# STM32H733xx register map
File version: 1.0
Registers are 32-bit, access not given, reset 0x0 unless marked. A register's access mark holds for its fields unless they carry their own. Offsets are from the block's base; [hi:lo] are bit positions; {n}, {i} and the like mark numbered series; 'fields as' and 'values as' point back to an identical list.

## FDCAN_CCU
Base 0x4000A800
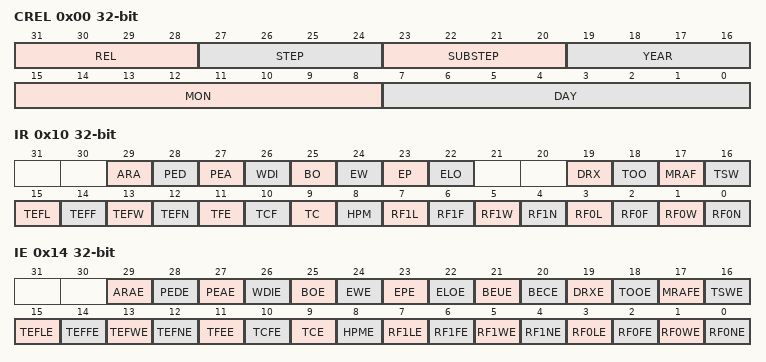
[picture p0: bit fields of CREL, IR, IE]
0x00 CREL
  [31:28] REL, [27:24] STEP, [23:20] SUBSTEP, [19:16] YEAR, [15:8] MON, [7:0] DAY
0x04 CCFG
0x08 CSTAT
0x0C CWD
0x10 IR
  [29] ARA, [28] PED, [27] PEA, [26] WDI, [25] BO, [24] EW, [23] EP, [22] ELO, [19] DRX, [18] TOO, [17] MRAF, [16] TSW, [15] TEFL, [14] TEFF, [13] TEFW, [12] TEFN, [11] TFE, [10] TCF, [9] TC, [8] HPM, [7] RF1L, [6] RF1F, [5] RF1W, [4] RF1N, [3] RF0L, [2] RF0F, [1] RF0W, [0] RF0N
0x14 IE
  [29] ARAE, [28] PEDE, [27] PEAE, [26] WDIE, [25] BOE, [24] EWE, [23] EPE, [22] ELOE, [21] BEUE, [20] BECE, [19] DRXE, [18] TOOE, [17] MRAFE, [16] TSWE, [15] TEFLE, [14] TEFFE, [13] TEFWE, [12] TEFNE, [11] TFEE, [10] TCFE, [9] TCE, [8] HPME, [7] RF1LE, [6] RF1FE, [5] RF1WE, [4] RF1NE, [3] RF0LE, [2] RF0FE, [1] RF0WE, [0] RF0NE

## SAI1
Base 0x40015800
Same registers: SAI4 0x58005400
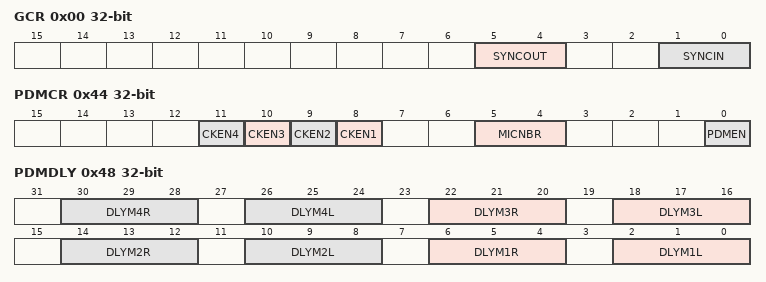
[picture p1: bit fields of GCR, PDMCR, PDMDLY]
0x00 GCR
  [5:4] SYNCOUT, [1:0] SYNCIN
0x04 CR1A
0x08 CR2A
0x10 FRCRA
0x1C SLOTRA
0x24 CR1B
0x28 CR2B
0x2C IMRA
0x30 FRCRB
0x3C SLOTRB
0x40 SRA
0x44 PDMCR
  [n+7] CKEN{n} (n=1..4), [5:4] MICNBR, [0] PDMEN
0x48 PDMDLY
  [8n-2:8n-4] DLYM{n}R (n=1..4), [8n-6:8n-8] DLYM{n}L (n=1..4)
0x4C IMRB
0x58 CLRFRA
0x60 SRB
0x74 DRA
0x78 CLRFRB
0x94 DRB

## DFSDM1
Base 0x40017800
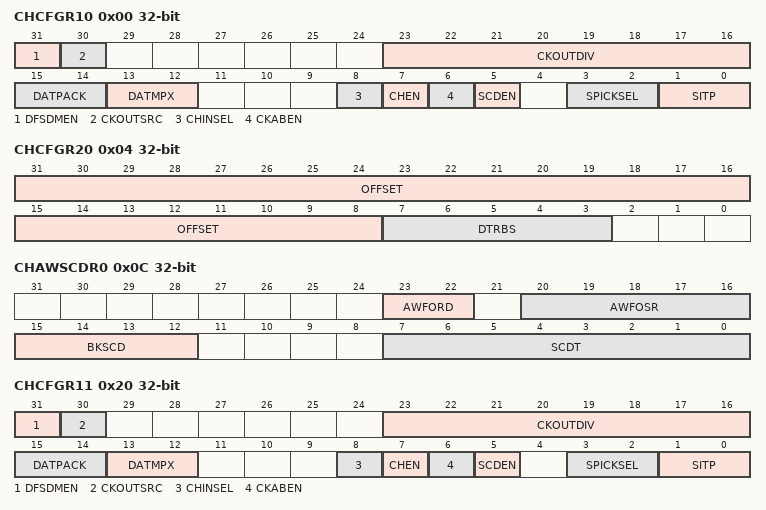
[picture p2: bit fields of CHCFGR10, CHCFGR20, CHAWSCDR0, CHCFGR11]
0x00 CHCFGR10
  [31] DFSDMEN, [30] CKOUTSRC, [23:16] CKOUTDIV, [15:14] DATPACK, [13:12] DATMPX, [8] CHINSEL, [7] CHEN, [6] CKABEN, [5] SCDEN, [3:2] SPICKSEL, [1:0] SITP
0x04 CHCFGR20
  [31:8] OFFSET, [7:3] DTRBS
0x0C CHAWSCDR0
  [23:22] AWFORD, [20:16] AWFOSR, [15:12] BKSCD, [7:0] SCDT
0x18 CHWDATAR0
0x20 CHCFGR11
  fields as CHCFGR10
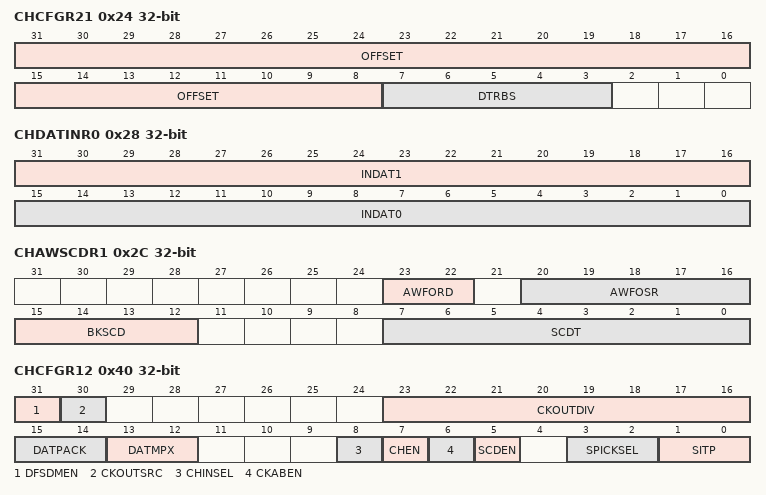
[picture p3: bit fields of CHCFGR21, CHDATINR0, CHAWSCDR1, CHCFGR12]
0x24 CHCFGR21
  [31:8] OFFSET, [7:3] DTRBS
0x28 CHDATINR0
  [31:16] INDAT1, [15:0] INDAT0
0x2C CHAWSCDR1
  [23:22] AWFORD, [20:16] AWFOSR, [15:12] BKSCD, [7:0] SCDT
0x38 CHWDATAR1
0x40 CHCFGR12
  fields as CHCFGR10
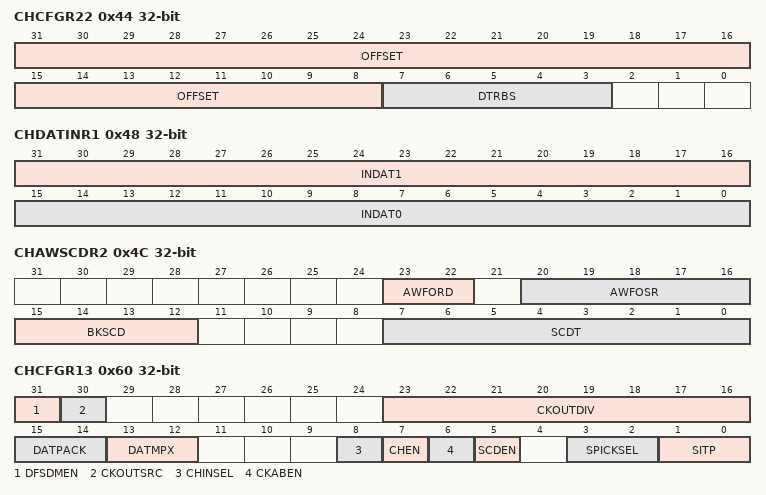
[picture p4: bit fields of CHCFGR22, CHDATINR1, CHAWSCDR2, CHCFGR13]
0x44 CHCFGR22
  [31:8] OFFSET, [7:3] DTRBS
0x48 CHDATINR1
  [31:16] INDAT1, [15:0] INDAT0
0x4C CHAWSCDR2
  [23:22] AWFORD, [20:16] AWFOSR, [15:12] BKSCD, [7:0] SCDT
0x58 CHWDATAR2
0x60 CHCFGR13
  fields as CHCFGR10
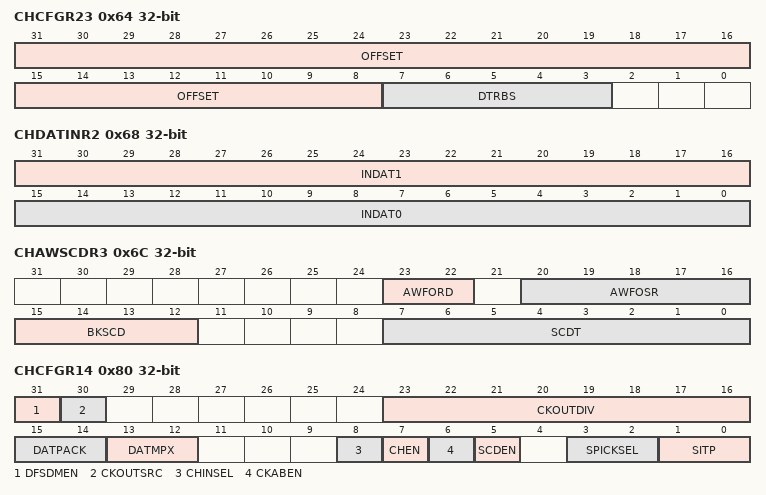
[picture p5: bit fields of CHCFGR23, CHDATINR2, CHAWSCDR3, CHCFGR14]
0x64 CHCFGR23
  [31:8] OFFSET, [7:3] DTRBS
0x68 CHDATINR2
  [31:16] INDAT1, [15:0] INDAT0
0x6C CHAWSCDR3
  [23:22] AWFORD, [20:16] AWFOSR, [15:12] BKSCD, [7:0] SCDT
0x78 CHWDATAR3
0x80 CHCFGR14
  fields as CHCFGR10
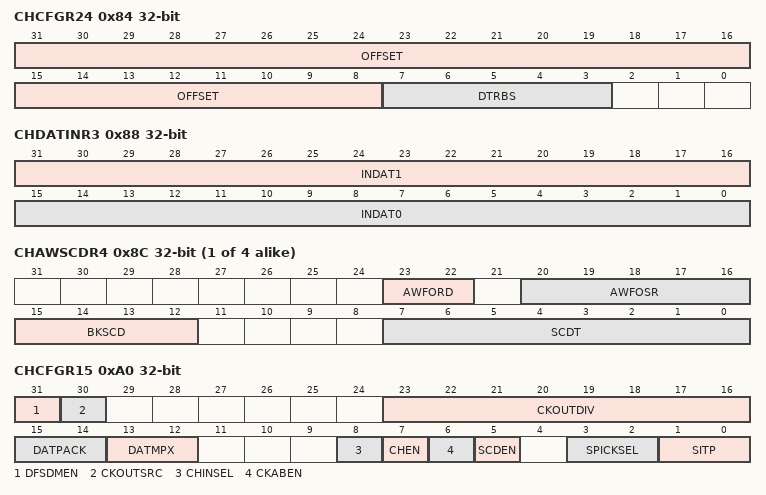
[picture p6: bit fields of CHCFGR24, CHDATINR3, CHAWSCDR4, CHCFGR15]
0x84 CHCFGR24
  [31:8] OFFSET, [7:3] DTRBS
0x88 CHDATINR3
  [31:16] INDAT1, [15:0] INDAT0
{0xC+0x20*i} CHAWSCDR{i} (i=4..7)
  [23:22] AWFORD, [20:16] AWFOSR, [15:12] BKSCD, [7:0] SCDT
{0x18+0x20*i} CHWDATAR{i} (i=4..7)
0xA0 CHCFGR15
  fields as CHCFGR10
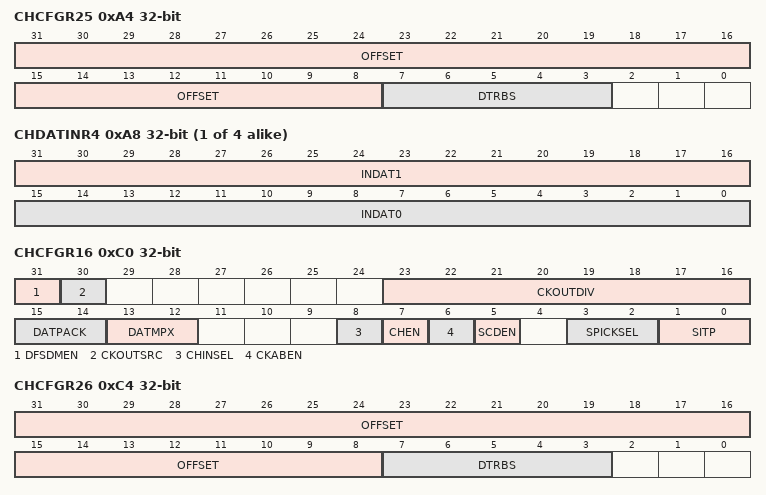
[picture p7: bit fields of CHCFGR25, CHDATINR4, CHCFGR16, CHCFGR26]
0xA4 CHCFGR25
  [31:8] OFFSET, [7:3] DTRBS
{0x28+0x20*i} CHDATINR{i} (i=4..7)
  [31:16] INDAT1, [15:0] INDAT0
0xC0 CHCFGR16
  fields as CHCFGR10
0xC4 CHCFGR26
  [31:8] OFFSET, [7:3] DTRBS
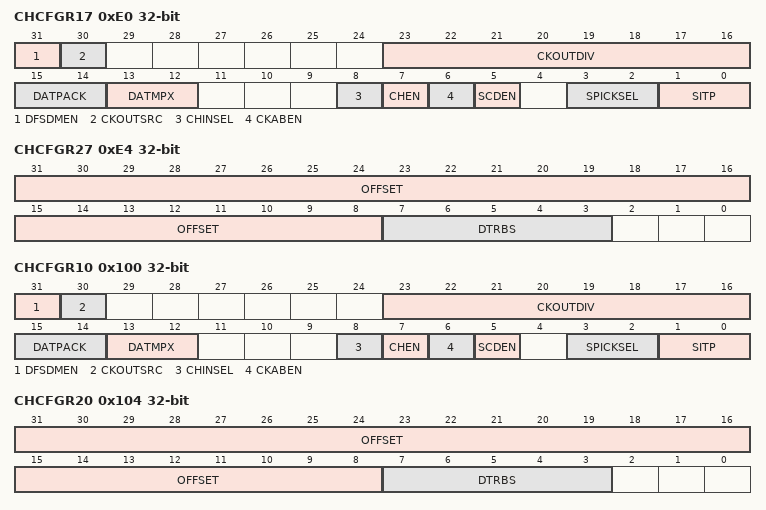
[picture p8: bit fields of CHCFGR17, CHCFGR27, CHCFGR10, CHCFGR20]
0xE0 CHCFGR17
  fields as CHCFGR10
0xE4 CHCFGR27
  [31:8] OFFSET, [7:3] DTRBS
0x100 CHCFGR10
  fields as CHCFGR10
0x104 CHCFGR20
  [31:8] OFFSET, [7:3] DTRBS
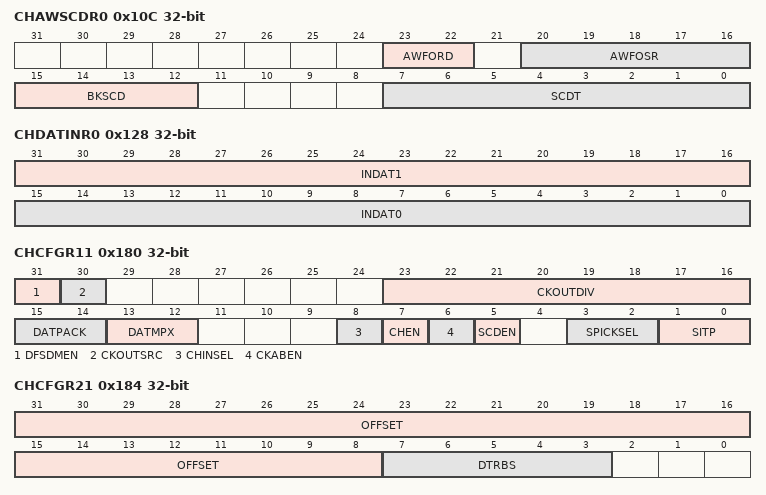
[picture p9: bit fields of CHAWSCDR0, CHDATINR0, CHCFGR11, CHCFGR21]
0x10C CHAWSCDR0
  [23:22] AWFORD, [20:16] AWFOSR, [15:12] BKSCD, [7:0] SCDT
0x118 CHWDATAR0
0x128 CHDATINR0
  [31:16] INDAT1, [15:0] INDAT0
0x180 CHCFGR11
  fields as CHCFGR10
0x184 CHCFGR21
  [31:8] OFFSET, [7:3] DTRBS
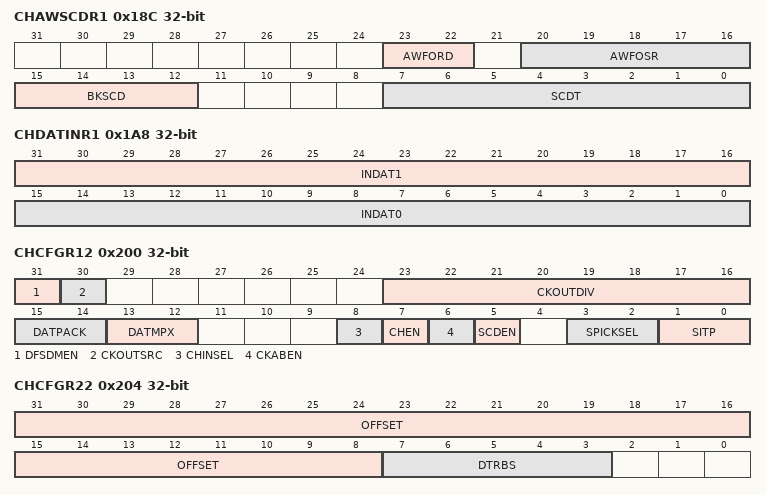
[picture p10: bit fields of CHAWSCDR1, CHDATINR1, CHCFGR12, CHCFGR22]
0x18C CHAWSCDR1
  [23:22] AWFORD, [20:16] AWFOSR, [15:12] BKSCD, [7:0] SCDT
0x198 CHWDATAR1
0x1A8 CHDATINR1
  [31:16] INDAT1, [15:0] INDAT0
0x200 CHCFGR12
  fields as CHCFGR10
0x204 CHCFGR22
  [31:8] OFFSET, [7:3] DTRBS
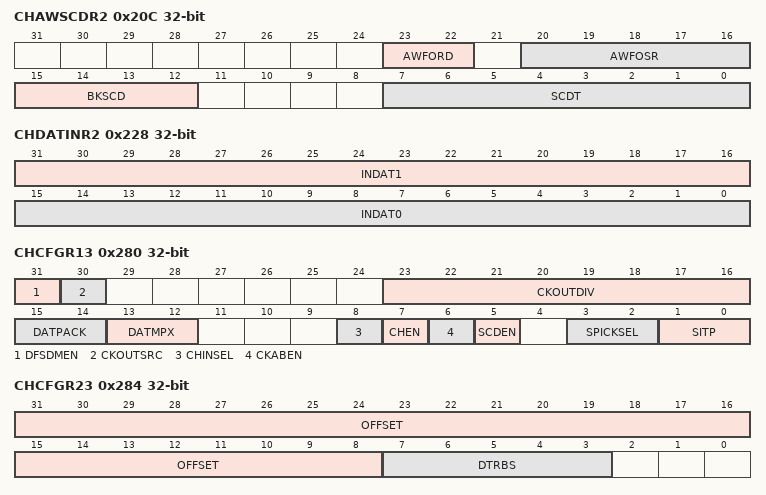
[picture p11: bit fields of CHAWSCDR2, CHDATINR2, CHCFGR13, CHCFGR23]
0x20C CHAWSCDR2
  [23:22] AWFORD, [20:16] AWFOSR, [15:12] BKSCD, [7:0] SCDT
0x218 CHWDATAR2
0x228 CHDATINR2
  [31:16] INDAT1, [15:0] INDAT0
0x280 CHCFGR13
  fields as CHCFGR10
0x284 CHCFGR23
  [31:8] OFFSET, [7:3] DTRBS
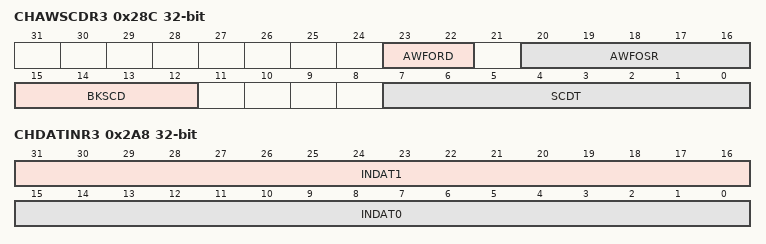
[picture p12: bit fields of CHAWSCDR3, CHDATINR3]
0x28C CHAWSCDR3
  [23:22] AWFORD, [20:16] AWFOSR, [15:12] BKSCD, [7:0] SCDT
0x298 CHWDATAR3
0x2A8 CHDATINR3
  [31:16] INDAT1, [15:0] INDAT0

## DMA1
Base 0x40020000
Same registers: DMA2 0x40020400
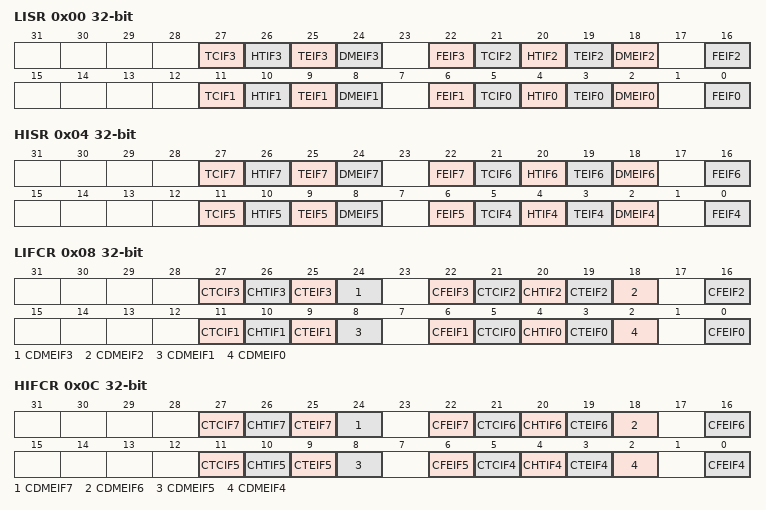
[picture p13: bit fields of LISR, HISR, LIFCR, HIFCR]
0x00 LISR
  [27] TCIF3, [26] HTIF3, [25] TEIF3, [24] DMEIF3, [22] FEIF3, [21] TCIF2, [20] HTIF2, [19] TEIF2, [18] DMEIF2, [16] FEIF2, [11] TCIF1, [10] HTIF1, [9] TEIF1, [8] DMEIF1, [6] FEIF1, [5] TCIF0, [4] HTIF0, [3] TEIF0, [2] DMEIF0, [0] FEIF0
0x04 HISR
  [27] TCIF7, [26] HTIF7, [25] TEIF7, [24] DMEIF7, [22] FEIF7, [21] TCIF6, [20] HTIF6, [19] TEIF6, [18] DMEIF6, [16] FEIF6, [11] TCIF5, [10] HTIF5, [9] TEIF5, [8] DMEIF5, [6] FEIF5, [5] TCIF4, [4] HTIF4, [3] TEIF4, [2] DMEIF4, [0] FEIF4
0x08 LIFCR
  [27] CTCIF3, [26] CHTIF3, [25] CTEIF3, [24] CDMEIF3, [22] CFEIF3, [21] CTCIF2, [20] CHTIF2, [19] CTEIF2, [18] CDMEIF2, [16] CFEIF2, [11] CTCIF1, [10] CHTIF1, [9] CTEIF1, [8] CDMEIF1, [6] CFEIF1, [5] CTCIF0, [4] CHTIF0, [3] CTEIF0, [2] CDMEIF0, [0] CFEIF0
0x0C HIFCR
  [27] CTCIF7, [26] CHTIF7, [25] CTEIF7, [24] CDMEIF7, [22] CFEIF7, [21] CTCIF6, [20] CHTIF6, [19] CTEIF6, [18] CDMEIF6, [16] CFEIF6, [11] CTCIF5, [10] CHTIF5, [9] CTEIF5, [8] CDMEIF5, [6] CFEIF5, [5] CTCIF4, [4] CHTIF4, [3] CTEIF4, [2] CDMEIF4, [0] CFEIF4
{0x10+0x18*i} CR{i} (i=0..7)
{0x14+0x18*i} NDTR{i} (i=0..7)
{0x1C+0x18*i} PAR{i} (i=0..7)
{0x28+0x18*i} M0AR{i} (i=0..7)
{0x38+0x18*i} M1AR{i} (i=0..7)
{0x4C+0x18*i} FCR{i} (i=0..7)
